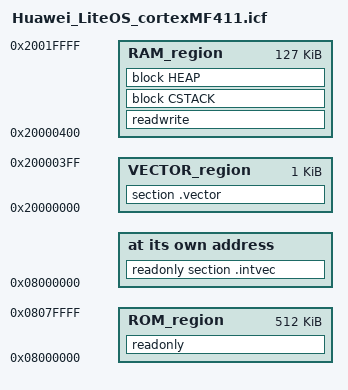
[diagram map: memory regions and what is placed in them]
/*###ICF### Section handled by ICF editor, don't touch! ****/
/*-Editor annotation file-*/
/* IcfEditorFile="$TOOLKIT_DIR$\config\ide\IcfEditor\cortex_v1_0.xml" */
/*-Specials-*/
define symbol __ICFEDIT_intvec_start__ = 0x08000000;
/*-Memory Regions-*/
define symbol __ICFEDIT_region_ROM_start__ = 0x08000000;
define symbol __ICFEDIT_region_ROM_end__   = 0x0807FFFF;
define symbol __ICFEDIT_region_RAM_start__ = 0x20000400;
define symbol __ICFEDIT_region_RAM_end__   = 0x2001FFFF;
/*-Sizes-*/
define symbol __ICFEDIT_size_cstack__ = 0x2000;
define symbol __ICFEDIT_size_heap__   = 0x2000;
/**** End of ICF editor section. ###ICF###*/

/*** VECTOR SIZE ***/
define symbol __ICFEDIT_region_VECTOR_start__ = 0x20000000;
define symbol __ICFEDIT_region_VECTOR_end__   = 0x200003FF;
/*** End of VECTOR SIZE ***/

define memory mem with size = 4G;
define region ROM_region   = mem:[from __ICFEDIT_region_ROM_start__   to __ICFEDIT_region_ROM_end__];
define region RAM_region   = mem:[from __ICFEDIT_region_RAM_start__   to __ICFEDIT_region_RAM_end__];

/*** VECTOR region***/
define region VECTOR_region   = mem:[from __ICFEDIT_region_VECTOR_start__   to __ICFEDIT_region_VECTOR_end__];
/*** End of VECTOR region***/

define block CSTACK    with alignment = 8, size = __ICFEDIT_size_cstack__   { };
define block HEAP      with alignment = 8, size = __ICFEDIT_size_heap__     { };

initialize by copy { readwrite };
do not initialize  { section .noinit };

place at address mem:__ICFEDIT_intvec_start__ { readonly section .intvec };

/*** VECTOR ***/
place in VECTOR_region  { section .vector };
/*** End of VECTOR ***/

place in ROM_region   { readonly };
place in RAM_region   { readwrite,
                        block CSTACK, block HEAP };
